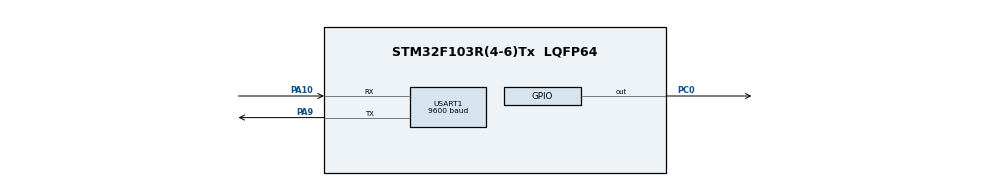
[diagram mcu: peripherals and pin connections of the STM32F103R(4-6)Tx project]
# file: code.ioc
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Mcu.Family=STM32F1
Dma.USART1_TX.0.MemInc=DMA_MINC_ENABLE
Dma.USART1_TX.0.PeriphInc=DMA_PINC_DISABLE
PA10.Mode=Asynchronous
USART1.BaudRate=9600
USART1.WordLength=WORDLENGTH_9B
PC0.Signal=GPIO_Output
VP_SYS_VS_ND.Mode=No_Debug
ProjectManager.StackSize=0x400
PA9.Mode=Asynchronous
Dma.USART1_TX.0.Priority=DMA_PRIORITY_LOW
Dma.USART1_TX.0.Direction=DMA_MEMORY_TO_PERIPH
ProjectManager.TargetToolchain=Makefile
PA9.Signal=USART1_TX
Dma.USART1_TX.0.Mode=DMA_NORMAL
board=custom
RCC.APB2Freq_Value=8000000
Dma.USART1_TX.0.PeriphDataAlignment=DMA_PDATAALIGN_BYTE
Mcu.Name=STM32F103R(4-6)Tx
Mcu.Package=LQFP64
USART1.VirtualMode=VM_ASYNC
Dma.USART1_TX.0.MemDataAlignment=DMA_MDATAALIGN_BYTE
PA10.Signal=USART1_RX
ProjectManager.HeapSize=0x200
Dma.USART1_TX.0.Instance=DMA1_Channel4
NVIC.PriorityGroup=NVIC_PRIORITYGROUP_4
NVIC.DMA1_Channel4_IRQn=true\:0\:0\:false\:false\:true\:false\:true
PC0.GPIO_PuPd=GPIO_PULLUP
Dma.Request0=USART1_TX
RCC.APB1Freq_Value=8000000
PC0.PinState=GPIO_PIN_RESET

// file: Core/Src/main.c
/* USER CODE BEGIN Header */
/**
 ******************************************************************************
 * @file           : main.c
 * @brief          : Main program body
 ******************************************************************************
 * @attention
 *
 * <h2><center>&copy; Copyright (c) 2021 STMicroelectronics.
 * All rights reserved.</center></h2>
 *
 * This software component is licensed by ST under BSD 3-Clause license,
 * the "License"; You may not use this file except in compliance with the
 * License. You may obtain a copy of the License at:
 *                        opensource.org/licenses/BSD-3-Clause
 *
 ******************************************************************************
 */
/* USER CODE END Header */
#include "main.h"
#include "dma.h"
#include "usart.h"
#include "gpio.h"

/* USER CODE BEGIN Includes */
#include <string.h>
/* USER CODE END Includes */

/* USER CODE BEGIN PV */
extern DMA_HandleTypeDef hdma_usart1_tx;
/* USER CODE END PV */

void SystemClock_Config(void);

int main(void)
{
  /* USER CODE BEGIN 1 */
	/*
	 * U ovom primeru bice demonstrirana upotreba DMA kontrolera za prenos jedne
	 * velike poruke iz memorije naseg mikrokontrolera na USART periferiju.
	 * Poruka ce biti odstampana na virtuelnom terminalu a LE Dioda ce biti
	 * Togglovana u prekidnoj rutini kada se kompletan prenos obavi.
	 * Postoji mogucnost da se generise prekid i na polovini i na kraju transfera
	 * podataka pomocu registrovanja odgovarajucih CallBack funkcija za DMA periferiju.
	 * Odgovarajuca prekidna rutina definisana je u stm32fxx_it.c fajlu.
	 */
	char msg[] ="Ova poruka je preneta putem DMA kontrolera transferom iz memorije"
				" na periferiju USART! LE dioda se Toggluje u prekidnoj rutini nakon"
				" zavrsenog prenosa podataka!\r";
  /* USER CODE END 1 */

  /* MCU Configuration--------------------------------------------------------*/

  /* Reset of all peripherals, Initializes the Flash interface and the Systick. */
  HAL_Init();

  /* Configure the system clock */
  SystemClock_Config();

  /* Initialize all configured peripherals */
  MX_GPIO_Init();
  MX_DMA_Init();
  MX_USART1_UART_Init();

  /* Infinite loop */
  /* USER CODE BEGIN WHILE */
  /*
   * Nakon konfiguracije odgovarajucih periferija u beskonacnoj petlji cemo na svakih
   * sekund prenositi odgovarajucu poruku pomocu DMA kontrolera. Da bismo omogucili
   * prenos podataka na USART periferiju putem DMA kontrolera neophodno je da u
   * kontrolnom registru USART periferije postavimo odgovarajuci bit USART_CR3_DMAT.
   * Alternativno, mogli smo da pozovemo funkciju HAL_UART_Transmit_DMA(huart, pData, Size)
   * koja bi samostalno postavila odgovarajuci bit i izvrsila prenos podataka. Izabrana je
   * prva opcija da bi se bolje demonstrirala upotreba DMA kontrolera pozivom funkcije
   * HAL_DMA_Start_IT kojoj se kao parametri prosledjuju: rucka na strukturu u kojoj su
   * konfigurisani svi neophodni parametri za prenos iz memorije na USART periferiju,
   * pocetna adresa sa koje ce se slati podaci, pocenta adresa na koju ce se smestati podaci
   * kao i broj podataka koji se prenosi. U prekidnoj rutini cemo resetovati odgovarajuci bit
   * u kontrolnom registru USART periferije da bi se ona mogla koristiti na drugim mestima
   * iz programskog koda, ukoliko bi bilo potrebe za tim.
   */
	while (1) {
		huart1.Instance->CR3 |= USART_CR3_DMAT;
		HAL_DMA_Start_IT(&hdma_usart1_tx, (uint32_t) msg,
				(uint32_t) &huart1.Instance->DR, strlen(msg));
		HAL_Delay(1000);
    /* USER CODE END WHILE */

	}
}

void SystemClock_Config(void)
{
  RCC_OscInitTypeDef RCC_OscInitStruct = {0};
  RCC_ClkInitTypeDef RCC_ClkInitStruct = {0};

  /** Initializes the RCC Oscillators according to the specified parameters
  * in the RCC_OscInitTypeDef structure.
  */
  RCC_OscInitStruct.OscillatorType = RCC_OSCILLATORTYPE_HSI;
  RCC_OscInitStruct.HSIState = RCC_HSI_ON;
  RCC_OscInitStruct.HSICalibrationValue = RCC_HSICALIBRATION_DEFAULT;
  RCC_OscInitStruct.PLL.PLLState = RCC_PLL_NONE;
  if (HAL_RCC_OscConfig(&RCC_OscInitStruct) != HAL_OK)
  {
    Error_Handler();
  }
  /** Initializes the CPU, AHB and APB buses clocks
  */
  RCC_ClkInitStruct.ClockType = RCC_CLOCKTYPE_HCLK|RCC_CLOCKTYPE_SYSCLK
                              |RCC_CLOCKTYPE_PCLK1|RCC_CLOCKTYPE_PCLK2;
  RCC_ClkInitStruct.SYSCLKSource = RCC_SYSCLKSOURCE_HSI;
  RCC_ClkInitStruct.AHBCLKDivider = RCC_SYSCLK_DIV1;
  RCC_ClkInitStruct.APB1CLKDivider = RCC_HCLK_DIV1;
  RCC_ClkInitStruct.APB2CLKDivider = RCC_HCLK_DIV1;

  if (HAL_RCC_ClockConfig(&RCC_ClkInitStruct, FLASH_LATENCY_0) != HAL_OK)
  {
    Error_Handler();
  }
}

void Error_Handler(void)
{
	__disable_irq();
	while (1) {
	}
}

/************************ (C) COPYRIGHT STMicroelectronics *****END OF FILE****/
